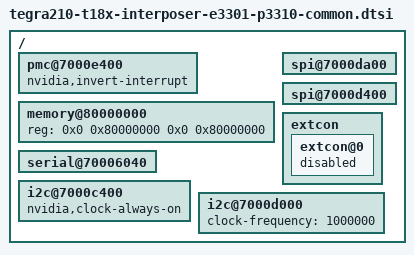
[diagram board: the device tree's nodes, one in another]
/*
 * tegra210-t18x-interposer-e3301-p3310-common.dtsi: Common DTSI for
 *	E3301-* and P3310-*.
 *
 * Copyright (c) 2015, NVIDIA CORPORATION.  All rights reserved.
 *
 * This program is free software; you can redistribute it and/or modify
 * it under the terms of the GNU General Public License as published by
 * the Free Software Foundation; version 2 of the License.
 *
 * This program is distributed in the hope that it will be useful, but WITHOUT
 * ANY WARRANTY; without even the implied warranty of MERCHANTABILITY or
 * FITNESS FOR A PARTICULAR PURPOSE.  See the GNU General Public License for
 * more details.
 *
 */

/dts-v1/;

/memreserve/ 0x80000000 0x00020000;

#include "tegra210-common.dtsi"

/ {
	#address-cells = <2>;
	#size-cells = <2>;

	pmc@7000e400 {
		nvidia,invert-interrupt;
	};

	memory@80000000 {
		device_type = "memory";
		reg = < 0x0 0x80000000 0x0 0x80000000 >;
	};

	serial@70006040 {
		status = "okay";
	};

	spi@7000da00 {
		status = "ok";
	};

	spi@7000d400 {
		status = "okay";
	};

	extcon {
		extcon@0 {
			status = "disabled";
		};
	};

	i2c@7000c400 {
		nvidia,clock-always-on;
	};

	i2c@7000d000 {
		clock-frequency = <1000000>;
	};
};
